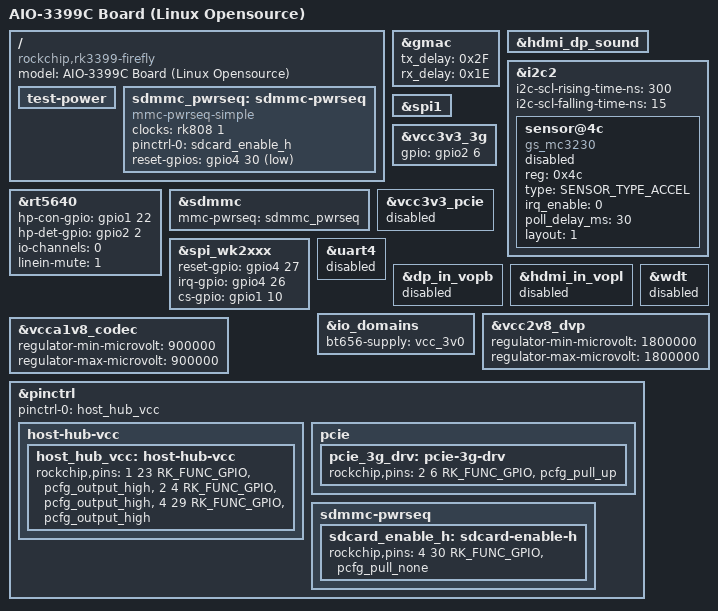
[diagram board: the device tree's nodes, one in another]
/*
 * Copyright (c) 2016 Fuzhou Rockchip Electronics Co., Ltd
 *
 * This file is dual-licensed: you can use it either under the terms
 * of the GPL or the X11 license, at your option. Note that this dual
 * licensing only applies to this file, and not this project as a
 * whole.
 *
 *  a) This file is free software; you can redistribute it and/or
 *     modify it under the terms of the GNU General Public License as
 *     published by the Free Software Foundation; either version 2 of the
 *     License, or (at your option) any later version.
 *
 *     This file is distributed in the hope that it will be useful,
 *     but WITHOUT ANY WARRANTY; without even the implied warranty of
 *     MERCHANTABILITY or FITNESS FOR A PARTICULAR PURPOSE.  See the
 *     GNU General Public License for more details.
 *
 * Or, alternatively,
 *     restriction, including without limitation the rights to use,
 *     copy, modify, merge, publish, distribute, sublicense, and/or
 *     sell copies of the Software, and to permit persons to whom the
 *     Software is furnished to do so, subject to the following
 *     conditions:
 *
 *     The above copyright notice and this permission notice shall be
 *     included in all copies or substantial portions of the Software.
 *
 *     THE SOFTWARE IS PROVIDED "AS IS", WITHOUT WARRANTY OF ANY KIND,
 *     EXPRESS OR IMPLIED, INCLUDING BUT NOT LIMITED TO THE WARRANTIES
 *     OF MERCHANTABILITY, FITNESS FOR A PARTICULAR PURPOSE AND
 *     NONINFRINGEMENT. IN NO EVENT SHALL THE AUTHORS OR COPYRIGHT
 *     HOLDERS BE LIABLE FOR ANY CLAIM, DAMAGES OR OTHER LIABILITY,
 *     WHETHER IN AN ACTION OF CONTRACT, TORT OR OTHERWISE, ARISING
 *     FROM, OUT OF OR IN CONNECTION WITH THE SOFTWARE OR THE USE OR
 *     OTHER DEALINGS IN THE SOFTWARE.
 */

/dts-v1/;

#include "rk3399-firefly-port.dtsi"
#include <dt-bindings/sensor-dev.h>

/ {
	model = "AIO-3399C Board (Linux Opensource)";
	compatible = "rockchip,rk3399-firefly", "rockchip,rk3399";

	test-power {
		status = "okay";
	};

	/delete-node/ vcc-sd;
	sdmmc_pwrseq: sdmmc-pwrseq {
		compatible = "mmc-pwrseq-simple";
		clocks = <&rk808 1>;
		clock-names = "ext_clock";
		pinctrl-names = "default";
		pinctrl-0 = <&sdcard_enable_h>;
		/*
		* On the module itself this is one of these (depending
		* on the actual card populated):
		* - SDIO_RESET_L_WL_REG_ON
		* - PDN (power down when low)
		*/
		reset-gpios = <&gpio4 30 GPIO_ACTIVE_LOW>; /* GPIO4_D6 */
	};
};

&gmac {
	tx_delay = <0x2F>;
	rx_delay = <0x1E>;
};

&hdmi_dp_sound {
	status = "okay";
};

&i2c2 {
	status = "okay";
	i2c-scl-rising-time-ns = <300>;
	i2c-scl-falling-time-ns = <15>;

	sensor@4c {
		status = "disabled";
		compatible = "gs_mc3230";
		reg = <0x4c>;
		type = <SENSOR_TYPE_ACCEL>;
		irq_enable = <0>;
		poll_delay_ms = <30>;
		layout = <1>;
	};
};

&rt5640 {
	hp-con-gpio = <&gpio1 22 GPIO_ACTIVE_HIGH>;
	hp-det-gpio = <&gpio2 2 GPIO_ACTIVE_HIGH>;
	io-channels = <0>;
	linein-mute = <1>;
};

&sdmmc {
	/delete-property/ vmmc-supply;
	mmc-pwrseq = <&sdmmc_pwrseq>;
};

&spi1 {
    status = "okay";
};

&spi_wk2xxx {
    status = "okay";
	reset-gpio = <&gpio4 27 GPIO_ACTIVE_HIGH>;
	irq-gpio = <&gpio4 26 IRQ_TYPE_EDGE_FALLING>;
	cs-gpio = <&gpio1 10 GPIO_ACTIVE_HIGH>;
};

&vcc3v3_3g {
	gpio = <&gpio2 6 GPIO_ACTIVE_HIGH>;
};

&vcc3v3_pcie {
    status = "disabled";
};

&uart4 {
    status = "disabled";
};

&dp_in_vopb {
	status = "disabled";
};

&hdmi_in_vopl {
	status = "disabled";
};

&wdt {
	status = "disabled";
};

&io_domains {
	bt656-supply = <&vcc_3v0>;
};

&vcc2v8_dvp {
	regulator-min-microvolt = <1800000>;
	regulator-max-microvolt = <1800000>;
};

&vcca1v8_codec {
	regulator-min-microvolt = <900000>;
	regulator-max-microvolt = <900000>;
};

&pinctrl {
	pinctrl-names = "default";
	pinctrl-0 = <&host_hub_vcc>;

	host-hub-vcc {
		host_hub_vcc: host-hub-vcc {
			rockchip,pins = <1 23 RK_FUNC_GPIO &pcfg_output_high>,
				<2 4 RK_FUNC_GPIO &pcfg_output_high>,
				<4 29 RK_FUNC_GPIO &pcfg_output_high>;
		};
	};

	pcie {
		pcie_3g_drv: pcie-3g-drv {
			rockchip,pins =
				<2 6 RK_FUNC_GPIO &pcfg_pull_up>;
		};
	};

	sdmmc-pwrseq {
		sdcard_enable_h: sdcard-enable-h {
			rockchip,pins =
				<4 30 RK_FUNC_GPIO &pcfg_pull_none>;
		};
	};
};
